# CY8C4xxx register map
File version: 0.1
Registers are 8-bit, read-write, no defined reset value unless marked. A register's access mark holds for its fields unless they carry their own. Offsets are from the block's base; [hi:lo] are bit positions.

## CSD — Capsense Controller
Base 0x40080000
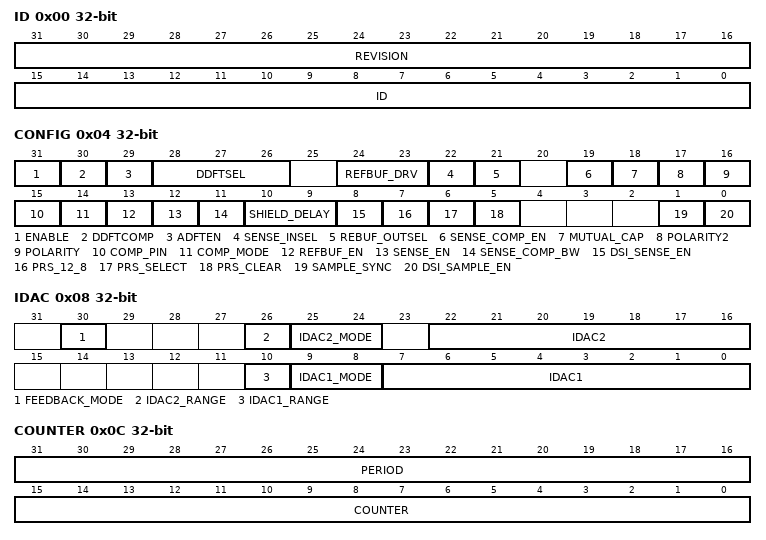
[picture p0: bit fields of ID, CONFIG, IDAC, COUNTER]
0x00 ID 32-bit — ID & Revision Number
  [31:16] REVISION ro — the version number is 0x0001
  [15:0] ID ro — the ID of CSD peripheral is 0xE0E1
0x04 CONFIG 32-bit — Configuration and Control
  [31] ENABLE — Master enable of the CSD IP. Must be set to 1 for any CSD operation to function.
  [30] DDFTCOMP — Changes comp_out signal for DFT purpose only. This signal can be routed to pins or other destinations using DDFTSEL
    0=REFBUFCOMP; 1=SENSECOMP
  [29] ADFTEN — When selected, convert IDAC1/2 outputs from current to voltage before sending to AMUXBUS-A/B. IDAC1/2 output currents and connectivity are determined by other CSD_CONFIG/CSD_IDAC settings same as in normal mode.
  [28:26] DDFTSEL — Changes the dsi_sample_out signal from its normal function (sample_out) to a selection of other DDFT signals.
    0=NORMAL; 1=CSD_SENSE; 2=CSD_SHIELD; 3=CLK_SAMPLE; 4=COMP_OUT
  [24:23] REFBUF_DRV — Current drive strength for reference buffer.
    0=OFF; 1=DRV_1; 2=DRV_2; 3=DRV_3
  [22] SENSE_INSEL — Selects how to connect the sensing comparator to the Cmod capacitor.
    0=SENSE_CHANNEL1; 1=SENSE_AMUXA
  [21] REBUF_OUTSEL — Selects which AMUXBUS the reference buffer connects to.
    0=AMUXA; 1=AMUXB
  [19] SENSE_COMP_EN — Turns on the sense comparator circuit. Must be done some time before enable SENSE_EN.?0: Sense comparator is powered off.?1: Sense comparator is powered on.
  [18] MUTUAL_CAP — Enables mutual cap sensing mode
    0=SELFCAP; 1=MUTUALCAP
  [17] POLARITY2 — For normal CSD operations this field is not used. When using the IDAC's for other-than-CSD purposes, this bit controls the IDAC2 polarity only.
    0=VSSIO; 1=VDDIO
  [16] POLARITY — Selects the polarity of the sensing operation. When using the IDAC's for other-than-CSD purposes, this bit controls the IDAC1 polarity only.
    0=VSSIO; 1=VDDIO
  [15] COMP_PIN — Connects either the Cmod or Csh_tank sense return line to the reference buffer comparator. This switch must be set to the same pin that is being charged up by the reference buffer (through the AMUXBUS settings in GPIO).
    0=CHANNEL1; 1=CHANNEL2
  [14] COMP_MODE — Selects between charging of the Cmod/Csh_tank capacitor using the GPIO digital output buffer or the CSD reference buffer. Note that using the GPIO requires proper configuraiton of the GPIO pin.
    0=CHARGE_BUF; 1=CHARGE_IO
  [13] REFBUF_EN — Enables the reference buffer/comparator circuits for charging Cmod/Csh_tank using the mode selected in COMP_MODE.
  [12] SENSE_EN — Enables the sense modulator output. Also turns on the IDAC compensation current as selected by CSD_IDAC.
  [11] SENSE_COMP_BW — Selects bandwidth for sensing comparator
    0=LOW; 1=HIGH
  [10:9] SHIELD_DELAY — Indicates the number of clk_hf clock cycles that csd_shield is delayed relative to csd_sense. Valid values are 0,1,2.
  [8] DSI_SENSE_EN — Enables the use of the dsi_sense_in input instead of the internally generated modulation signal to drive csd_sense and csd_shield signals.
  [7] PRS_12_8 — Selects between 8 or 12b PRS sequence
    0=Cy8B; 1=Cy12B
  [6] PRS_SELECT — Selects between PRS or simple divide by 2 sense modulation.
    0=DIV2; 1=PRS
  [5] PRS_CLEAR write-once — When set, forces the pseudo-random generator to it's initial state. Note that it may take some time for this setting to take effect depending on the clock frequency used for clk_csd1. Hardware clears this bit at the same time PRS is cleared.
  [1] SAMPLE_SYNC — Enables double synchronizing of sample input from DSI (only relevant when DSI_SAMPLE_EN=1).
  [0] DSI_SAMPLE_EN — Enables the use of the dsi_sample_in input instead of the comparator output to strobe COUNTER.
0x08 IDAC 32-bit — IDAC Configuration
  [30] FEEDBACK_MODE — This bit controls whether, during CSD operation, the IDAC is controlled from the sampling flip-flop or directly from the comparator.
    0=FLOP; 1=COMP
  [26] IDAC2_RANGE — Current multiplier setting for IDAC2.
    0=Cy4X; 1=Cy8X
  [25:24] IDAC2_MODE — Controls the usage mode of IDAC2
    0=OFF; 1=FIXED; 2=VARIABLE; 3=DSI
  [22:16] IDAC2 — Current setting for IDAC2 (7 bits).
  [10] IDAC1_RANGE — Current multiplier setting for IDAC1.
    0=Cy4X; 1=Cy8X
  [9:8] IDAC1_MODE — Controls the usage mode of IDAC1
    0=OFF; 1=FIXED; 2=VARIABLE; 3=DSI
  [7:0] IDAC1 — Current setting for IDAC1 (8 bits).
0x0C COUNTER 32-bit — CSD Counter Register
  [31:16] PERIOD — The remaining period (in clk_csd1 cycles) during which COUNTER will count the comparator output count.?Firmware will write this field to the desired period, after which it will start counting down to 0. Upon completion of the sense operation, this field will be 0. Writing a non-0 value to this register initiates a sensing operation. It is assumed that the modulation is properly configured, all pins are properly selected and configured and that sense currents are flowing before this field is written.
  [15:0] COUNTER — This field increments whenever the comparator is sampled and the sample is 1. Firmware typically writes 0 to this field whenever a new sense operation is initiated by writing a non-0 value to PERIOD.
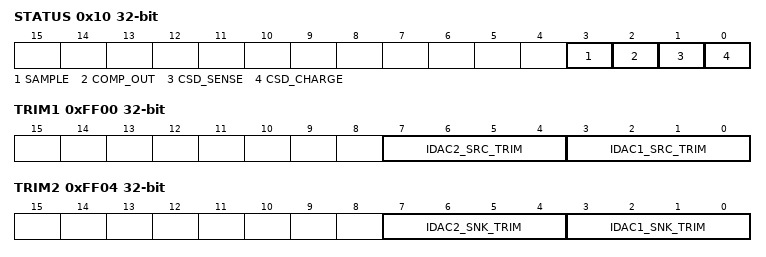
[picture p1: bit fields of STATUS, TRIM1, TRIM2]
0x10 STATUS 32-bit
  [3] SAMPLE ro — Output of main sensing comparator.
  [2] COMP_OUT ro — Output of reference buffer comparator used to charge up Cmod or Csh_tank.
    0=C_LT_VREF; 1=C_GT_VREF
  [1] CSD_SENSE ro — Signal used to drive the Cs switches.
  [0] CSD_CHARGE ro — Qualified, and possible inverted value of COMP_OUT that is used to drive GPIO's charging Cmod or Csh_tank.
0x14 INTR 32-bit — CSD Interrupt Request Register
  [0] CSD write-once — The CSD IRQ bit is set. Firmware must clear this bit as part of the interrupt handler.
0x18 INTR_SET 32-bit — CSD Interrupt set register
  [0] CSD write-once — Write with '1' to set corresponding bit in interrupt request register.
0xFF00 TRIM1 32-bit — CSD Trim Register
  [7:4] IDAC2_SRC_TRIM — IDAC2 trim bits for gain control in current source mode
  [3:0] IDAC1_SRC_TRIM — IDAC1 trim bits for gain control in current source mode
0xFF04 TRIM2 32-bit — CSD Trim Register
  [7:4] IDAC2_SNK_TRIM — IDAC2 trim bits for gain control in current sink mode
  [3:0] IDAC1_SNK_TRIM — IDAC1 trim bits for gain control in current sink mode
